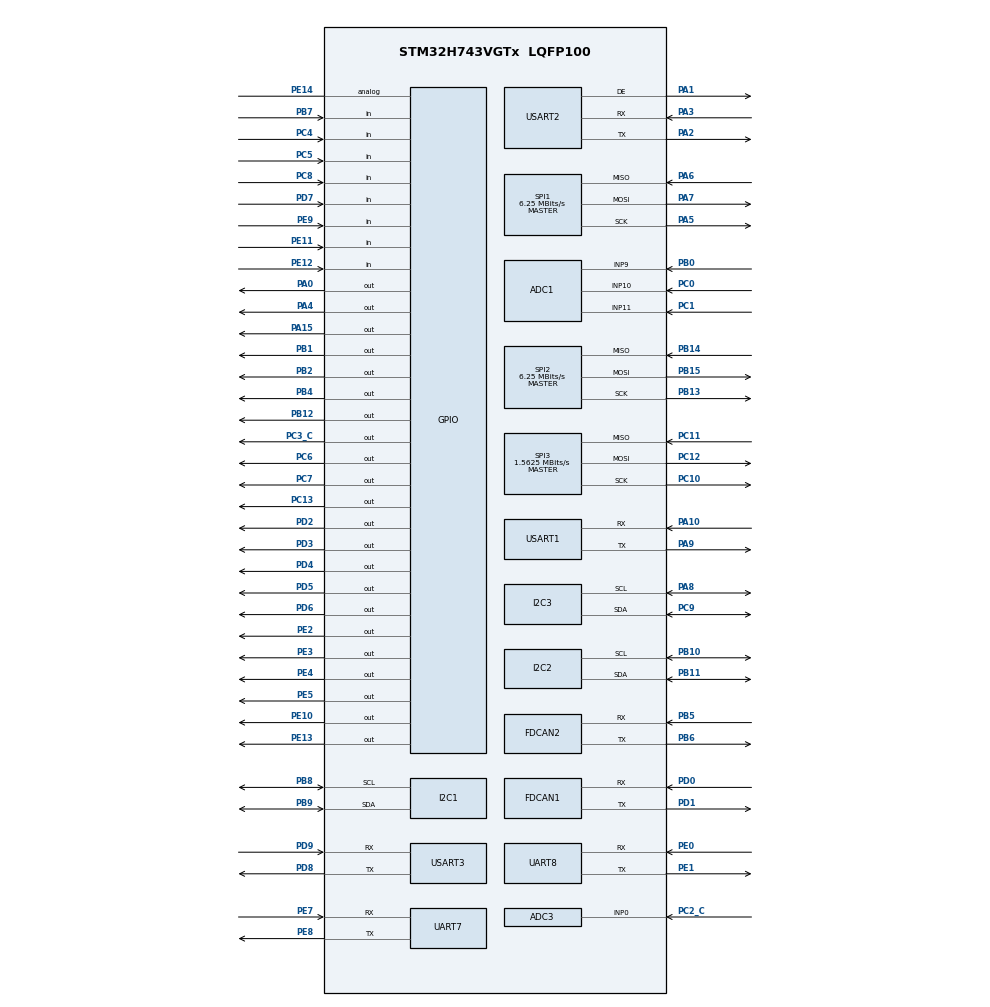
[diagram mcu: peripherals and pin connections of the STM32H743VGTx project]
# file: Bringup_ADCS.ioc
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ADC1.Channel-1\#ChannelRegularConversion=ADC_CHANNEL_9
ADC1.ClockPrescaler=ADC_CLOCK_ASYNC_DIV4
ADC1.NbrOfConversionFlag=1
ADC1.OffsetNumber-1\#ChannelRegularConversion=ADC_OFFSET_NONE
ADC1.OffsetSignedSaturation-1\#ChannelRegularConversion=DISABLE
ADC1.Rank-1\#ChannelRegularConversion=1
ADC1.SamplingTime-1\#ChannelRegularConversion=ADC_SAMPLETIME_810CYCLES_5
ADC1.master=1
ADC3.Channel-1\#ChannelRegularConversion=ADC_CHANNEL_0
ADC3.ClockPrescaler=ADC_CLOCK_ASYNC_DIV4
ADC3.NbrOfConversionFlag=1
ADC3.OffsetNumber-1\#ChannelRegularConversion=ADC_OFFSET_NONE
ADC3.OffsetSignedSaturation-1\#ChannelRegularConversion=DISABLE
ADC3.Rank-1\#ChannelRegularConversion=1
ADC3.SamplingTime-1\#ChannelRegularConversion=ADC_SAMPLETIME_1CYCLE_5
CORTEX_M7.default_mode_Activation=1
FDCAN1.AutoRetransmission=ENABLE
FDCAN1.CalculateBaudRateNominal=500000
FDCAN1.CalculateTimeBitNominal=2000
FDCAN1.CalculateTimeQuantumNominal=100.0
FDCAN1.NominalPrescaler=5
FDCAN1.NominalTimeSeg1=15
FDCAN1.NominalTimeSeg2=4
FDCAN1.RxFifo0ElmtsNbr=8
FDCAN1.StdFiltersNbr=1
FDCAN1.TxFifoQueueElmtsNbr=8
FDCAN2.AutoRetransmission=ENABLE
FDCAN2.CalculateBaudRateNominal=500000
FDCAN2.CalculateTimeBitNominal=2000
FDCAN2.CalculateTimeQuantumNominal=100.0
FDCAN2.MessageRAMOffset=128
FDCAN2.NominalPrescaler=5
FDCAN2.NominalTimeSeg1=15
FDCAN2.NominalTimeSeg2=4
FDCAN2.RxFifo0ElmtsNbr=8
FDCAN2.StdFiltersNbr=1
FDCAN2.TxFifoQueueElmtsNbr=8
FREERTOS.Tasks01=defaultTask,24,128,StartDefaultTask,Default,NULL,Dynamic,NULL,NULL
I2C1.Timing=0x00707CBB
I2C2.Timing=0x00707CBB
I2C3.Timing=0x00707CBB
Mcu.Family=STM32H7
Mcu.Name=STM32H743VGTx
Mcu.Package=LQFP100
NVIC.PriorityGroup=NVIC_PRIORITYGROUP_4
NVIC.TIM6_DAC_IRQn=true\:15\:0\:false\:false\:true\:false\:false\:true\:true
NVIC.TimeBase=TIM6_DAC_IRQn
NVIC.TimeBaseIP=TIM6
PA0.Signal=GPIO_Output
PA1.Mode=Hardware Flow Control (RS485)
PA1.Signal=USART2_DE
PA10.Mode=Asynchronous
PA10.Signal=USART1_RX
PA13\ (JTMS/SWDIO).Mode=Serial_Wire
PA13\ (JTMS/SWDIO).Signal=DEBUG_JTMS-SWDIO
PA14\ (JTCK/SWCLK).Mode=Serial_Wire
PA14\ (JTCK/SWCLK).Signal=DEBUG_JTCK-SWCLK
PA15\ (JTDI).Signal=GPIO_Output
PA2.Mode=Asynchronous
PA2.Signal=USART2_TX
PA3.Mode=Asynchronous
PA3.Signal=USART2_RX
PA4.PinState=GPIO_PIN_SET
PA4.Signal=GPIO_Output
PA5.Mode=Full_Duplex_Master
PA5.Signal=SPI1_SCK
PA6.Mode=Full_Duplex_Master
PA6.Signal=SPI1_MISO
PA7.Mode=Full_Duplex_Master
PA7.Signal=SPI1_MOSI
PA8.Mode=I2C
PA8.Signal=I2C3_SCL
PA9.Mode=Asynchronous
PA9.Signal=USART1_TX
PB0.Signal=ADCx_INP9
PB1.Signal=GPIO_Output
PB10.Mode=I2C
PB10.Signal=I2C2_SCL
PB11.Mode=I2C
PB11.Signal=I2C2_SDA
PB12.PinState=GPIO_PIN_SET
PB12.Signal=GPIO_Output
PB13.Mode=Full_Duplex_Master
PB13.Signal=SPI2_SCK
PB14.Mode=Full_Duplex_Master
PB14.Signal=SPI2_MISO
PB15.Mode=Full_Duplex_Master
PB15.Signal=SPI2_MOSI
PB2.Signal=GPIO_Output
PB4\ (NJTRST).Signal=GPIO_Output
PB5.Mode=FDCAN_Activate
PB5.Signal=FDCAN2_RX
PB6.Mode=FDCAN_Activate
PB6.Signal=FDCAN2_TX
PB7.Signal=GPIO_Input
PB8.Mode=I2C
PB8.Signal=I2C1_SCL
PB9.Mode=I2C
PB9.Signal=I2C1_SDA
PC0.Signal=ADCx_INP10
PC1.Signal=ADCx_INP11
PC10.Mode=Full_Duplex_Master
PC10.Signal=SPI3_SCK
PC11.Mode=Full_Duplex_Master
PC11.Signal=SPI3_MISO
PC12.Mode=Full_Duplex_Master
PC12.Signal=SPI3_MOSI
PC13.Signal=GPIO_Output
PC14-OSC32_IN\ (OSC32_IN).Mode=LSE-External-Oscillator
PC14-OSC32_IN\ (OSC32_IN).Signal=RCC_OSC32_IN
PC15-OSC32_OUT\ (OSC32_OUT).Mode=LSE-External-Oscillator
PC15-OSC32_OUT\ (OSC32_OUT).Signal=RCC_OSC32_OUT
PC2_C.Mode=IN0-Single-Ended
PC2_C.Signal=ADC3_INP0
PC3_C.PinState=GPIO_PIN_SET
PC3_C.Signal=GPIO_Output
PC4.Signal=GPIO_Input
PC5.Signal=GPIO_Input
PC6.Signal=GPIO_Output
PC7.Signal=GPIO_Output
PC8.Signal=GPIO_Input
PC9.Mode=I2C
PC9.Signal=I2C3_SDA
PD0.Mode=FDCAN_Activate
PD0.Signal=FDCAN1_RX
PD1.Mode=FDCAN_Activate
PD1.Signal=FDCAN1_TX
PD2.Signal=GPIO_Output
PD3.Signal=GPIO_Output
PD4.Signal=GPIO_Output
PD5.Signal=GPIO_Output
PD6.PinState=GPIO_PIN_SET
PD6.Signal=GPIO_Output
PD7.Signal=GPIO_Input
PD8.Mode=Asynchronous
PD8.Signal=USART3_TX
PD9.Mode=Asynchronous
PD9.Signal=USART3_RX
PE0.Mode=Asynchronous
PE0.Signal=UART8_RX
PE1.Mode=Asynchronous
PE1.Signal=UART8_TX
PE10.Signal=GPIO_Output
PE11.Signal=GPIO_Input
PE12.Signal=GPIO_Input
PE13.Signal=GPIO_Output
PE14.Signal=GPIO_Analog
PE2.Signal=GPIO_Output
PE3.Signal=GPIO_Output
PE4.Signal=GPIO_Output
PE5.Signal=GPIO_Output
PE7.Mode=Asynchronous
PE7.Signal=UART7_RX
PE8.Mode=Asynchronous
PE8.Signal=UART7_TX
PE9.Signal=GPIO_Input
PH0-OSC_IN\ (PH0).Mode=HSE-External-Oscillator
PH0-OSC_IN\ (PH0).Signal=RCC_OSC_IN
PH1-OSC_OUT\ (PH1).Mode=HSE-External-Oscillator
PH1-OSC_OUT\ (PH1).Signal=RCC_OSC_OUT
ProjectManager.HeapSize=0x200
ProjectManager.StackSize=0x400
ProjectManager.TargetToolchain=CMake
RCC.ADCFreq_Value=75000000
RCC.APB1Freq_Value=32000000
RCC.APB2Freq_Value=32000000
RCC.APB3Freq_Value=64000000
RCC.APB4Freq_Value=64000000
RCC.CKPERSourceSelection=RCC_CLKPSOURCE_HSE
RCC.CortexFreq_Value=64000000
RCC.D2PPRE1=RCC_APB1_DIV2
RCC.D2PPRE2=RCC_APB2_DIV2
RCC.DIVM1=2
RCC.DIVM2=2
RCC.DIVN1=12
RCC.DIVN2=12
RCC.DIVQ1=3
RCC.HCLKFreq_Value=64000000
RCC.PLL2FRACN=0
RCC.PLLFRACN=0
RCC.PLLSourceVirtual=RCC_PLLSOURCE_HSE
RCC.SYSCLKFreq_VALUE=64000000
RCC.USBFreq_Value=50000000
SH.ADCx_INP10.0=ADC1_INP10,IN10-Single-Ended
SH.ADCx_INP11.0=ADC1_INP11,IN11-Single-Ended
SH.ADCx_INP9.0=ADC1_INP9,IN9-Single-Ended
SPI1.BaudRatePrescaler=SPI_BAUDRATEPRESCALER_8
SPI1.CalculateBaudRate=6.25 MBits/s
SPI1.DataSize=SPI_DATASIZE_8BIT
SPI1.Direction=SPI_DIRECTION_2LINES
SPI1.Mode=SPI_MODE_MASTER
SPI1.VirtualType=VM_MASTER
SPI2.BaudRatePrescaler=SPI_BAUDRATEPRESCALER_8
SPI2.CalculateBaudRate=6.25 MBits/s
SPI2.DataSize=SPI_DATASIZE_8BIT
SPI2.Direction=SPI_DIRECTION_2LINES
SPI2.Mode=SPI_MODE_MASTER
SPI2.VirtualType=VM_MASTER
SPI3.BaudRatePrescaler=SPI_BAUDRATEPRESCALER_32
SPI3.CLKPhase=SPI_PHASE_2EDGE
SPI3.CalculateBaudRate=1.5625 MBits/s
SPI3.DataSize=SPI_DATASIZE_16BIT
SPI3.Direction=SPI_DIRECTION_2LINES
SPI3.Mode=SPI_MODE_MASTER
SPI3.VirtualType=VM_MASTER
USART1.VirtualMode-Asynchronous=VM_ASYNC
USART2.VirtualMode-Asynchronous=VM_ASYNC
USART2.VirtualMode-Hardware\ Flow\ Control\ (RS485)=VM_ASYNC
USART3.VirtualMode-Asynchronous=VM_ASYNC
VP_FREERTOS_VS_CMSIS_V2.Mode=CMSIS_V2
VP_MEMORYMAP_VS_MEMORYMAP.Mode=CurAppReg
VP_SYS_VS_tim6.Mode=TIM6
board=custom

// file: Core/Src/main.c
/* USER CODE BEGIN Header */
/**
  ******************************************************************************
  * @file           : main.c
  * @brief          : Main program body
  ******************************************************************************
  * @attention
  *
  * Copyright (c) 2026 STMicroelectronics.
  * All rights reserved.
  *
  * This software is licensed under terms that can be found in the LICENSE file
  * in the root directory of this software component.
  * If no LICENSE file comes with this software, it is provided AS-IS.
  *
  ******************************************************************************
  */
/* USER CODE END Header */
#include "main.h"
#include "cmsis_os.h"

/* USER CODE BEGIN Includes */
#include "app_tasks.h"
/* USER CODE END Includes */

ADC_HandleTypeDef hadc1;
ADC_HandleTypeDef hadc3;

FDCAN_HandleTypeDef hfdcan1;
FDCAN_HandleTypeDef hfdcan2;

I2C_HandleTypeDef hi2c1;
I2C_HandleTypeDef hi2c2;
I2C_HandleTypeDef hi2c3;

SPI_HandleTypeDef hspi1;
SPI_HandleTypeDef hspi2;
SPI_HandleTypeDef hspi3;

UART_HandleTypeDef huart7;
UART_HandleTypeDef huart8;
UART_HandleTypeDef huart1;
UART_HandleTypeDef huart2;
UART_HandleTypeDef huart3;

/* Definitions for defaultTask */
osThreadId_t defaultTaskHandle;
const osThreadAttr_t defaultTask_attributes = {
  .name = "defaultTask",
  .stack_size = 128 * 4,
  .priority = (osPriority_t) osPriorityNormal,
};

void SystemClock_Config(void);
void PeriphCommonClock_Config(void);
static void MPU_Config(void);
static void MX_GPIO_Init(void);
static void MX_ADC1_Init(void);
static void MX_ADC3_Init(void);
static void MX_FDCAN1_Init(void);
static void MX_FDCAN2_Init(void);
static void MX_I2C1_Init(void);
static void MX_I2C2_Init(void);
static void MX_I2C3_Init(void);
static void MX_SPI1_Init(void);
static void MX_SPI2_Init(void);
static void MX_SPI3_Init(void);
static void MX_UART7_Init(void);
static void MX_UART8_Init(void);
static void MX_USART1_UART_Init(void);
static void MX_USART2_UART_Init(void);
static void MX_USART3_UART_Init(void);
void StartDefaultTask(void *argument);

int main(void)
{

  /* MPU Configuration--------------------------------------------------------*/
  MPU_Config();

  /* MCU Configuration--------------------------------------------------------*/

  /* Reset of all peripherals, Initializes the Flash interface and the Systick. */
  HAL_Init();

  /* Configure the system clock */
  SystemClock_Config();

  /* Configure the peripherals common clocks */
  PeriphCommonClock_Config();

  /* Initialize all configured peripherals */
  MX_GPIO_Init();
  MX_ADC1_Init();
  MX_ADC3_Init();
  MX_FDCAN1_Init();
  MX_FDCAN2_Init();
  MX_I2C1_Init();
  MX_I2C2_Init();
  MX_I2C3_Init();
  MX_SPI1_Init();
  MX_SPI2_Init();
  MX_SPI3_Init();
  MX_UART7_Init();
  MX_UART8_Init();
  MX_USART1_UART_Init();
  MX_USART2_UART_Init();
  MX_USART3_UART_Init();

  /* Init scheduler */
  osKernelInitialize();

  /* Create the thread(s) */
  /* creation of defaultTask */
  defaultTaskHandle = osThreadNew(StartDefaultTask, NULL, &defaultTask_attributes);

  /* USER CODE BEGIN RTOS_THREADS */
  app_tasks_init();
  /* USER CODE END RTOS_THREADS */

  /* Start scheduler */
  osKernelStart();

  /* We should never get here as control is now taken by the scheduler */

  /* Infinite loop */
  while (1)
  {

  }
}

void SystemClock_Config(void)
{
  RCC_OscInitTypeDef RCC_OscInitStruct = {0};
  RCC_ClkInitTypeDef RCC_ClkInitStruct = {0};

  /** Supply configuration update enable
  */
  HAL_PWREx_ConfigSupply(PWR_LDO_SUPPLY);

  /** Configure the main internal regulator output voltage
  */
  __HAL_PWR_VOLTAGESCALING_CONFIG(PWR_REGULATOR_VOLTAGE_SCALE3);

  while(!__HAL_PWR_GET_FLAG(PWR_FLAG_VOSRDY)) {}

  /** Initializes the RCC Oscillators according to the specified parameters
  * in the RCC_OscInitTypeDef structure.
  */
  RCC_OscInitStruct.OscillatorType = RCC_OSCILLATORTYPE_HSI|RCC_OSCILLATORTYPE_HSE;
  RCC_OscInitStruct.HSEState = RCC_HSE_ON;
  RCC_OscInitStruct.HSIState = RCC_HSI_DIV1;
  RCC_OscInitStruct.HSICalibrationValue = RCC_HSICALIBRATION_DEFAULT;
  RCC_OscInitStruct.PLL.PLLState = RCC_PLL_ON;
  RCC_OscInitStruct.PLL.PLLSource = RCC_PLLSOURCE_HSE;
  RCC_OscInitStruct.PLL.PLLM = 2;
  RCC_OscInitStruct.PLL.PLLN = 12;
  RCC_OscInitStruct.PLL.PLLP = 2;
  RCC_OscInitStruct.PLL.PLLQ = 3;
  RCC_OscInitStruct.PLL.PLLR = 2;
  RCC_OscInitStruct.PLL.PLLRGE = RCC_PLL1VCIRANGE_3;
  RCC_OscInitStruct.PLL.PLLVCOSEL = RCC_PLL1VCOMEDIUM;
  RCC_OscInitStruct.PLL.PLLFRACN = 0;
  if (HAL_RCC_OscConfig(&RCC_OscInitStruct) != HAL_OK)
  {
    Error_Handler();
  }

  /** Initializes the CPU, AHB and APB buses clocks
  */
  RCC_ClkInitStruct.ClockType = RCC_CLOCKTYPE_HCLK|RCC_CLOCKTYPE_SYSCLK
                              |RCC_CLOCKTYPE_PCLK1|RCC_CLOCKTYPE_PCLK2
                              |RCC_CLOCKTYPE_D3PCLK1|RCC_CLOCKTYPE_D1PCLK1;
  RCC_ClkInitStruct.SYSCLKSource = RCC_SYSCLKSOURCE_HSI;
  RCC_ClkInitStruct.SYSCLKDivider = RCC_SYSCLK_DIV1;
  RCC_ClkInitStruct.AHBCLKDivider = RCC_HCLK_DIV1;
  RCC_ClkInitStruct.APB3CLKDivider = RCC_APB3_DIV1;
  RCC_ClkInitStruct.APB1CLKDivider = RCC_APB1_DIV2;
  RCC_ClkInitStruct.APB2CLKDivider = RCC_APB2_DIV2;
  RCC_ClkInitStruct.APB4CLKDivider = RCC_APB4_DIV1;

  if (HAL_RCC_ClockConfig(&RCC_ClkInitStruct, FLASH_LATENCY_1) != HAL_OK)
  {
    Error_Handler();
  }
}

void PeriphCommonClock_Config(void)
{
  RCC_PeriphCLKInitTypeDef PeriphClkInitStruct = {0};

  /** Initializes the peripherals clock
  */
  PeriphClkInitStruct.PeriphClockSelection = RCC_PERIPHCLK_ADC;
  PeriphClkInitStruct.PLL2.PLL2M = 2;
  PeriphClkInitStruct.PLL2.PLL2N = 12;
  PeriphClkInitStruct.PLL2.PLL2P = 2;
  PeriphClkInitStruct.PLL2.PLL2Q = 2;
  PeriphClkInitStruct.PLL2.PLL2R = 2;
  PeriphClkInitStruct.PLL2.PLL2RGE = RCC_PLL2VCIRANGE_3;
  PeriphClkInitStruct.PLL2.PLL2VCOSEL = RCC_PLL2VCOMEDIUM;
  PeriphClkInitStruct.PLL2.PLL2FRACN = 0;
  PeriphClkInitStruct.AdcClockSelection = RCC_ADCCLKSOURCE_PLL2;
  if (HAL_RCCEx_PeriphCLKConfig(&PeriphClkInitStruct) != HAL_OK)
  {
    Error_Handler();
  }
}

static void MX_ADC1_Init(void)
{

  ADC_MultiModeTypeDef multimode = {0};
  ADC_ChannelConfTypeDef sConfig = {0};

  /** Common config
  */
  hadc1.Instance = ADC1;
  hadc1.Init.ClockPrescaler = ADC_CLOCK_ASYNC_DIV4;
  hadc1.Init.Resolution = ADC_RESOLUTION_16B;
  hadc1.Init.ScanConvMode = ADC_SCAN_DISABLE;
  hadc1.Init.EOCSelection = ADC_EOC_SINGLE_CONV;
  hadc1.Init.LowPowerAutoWait = DISABLE;
  hadc1.Init.ContinuousConvMode = DISABLE;
  hadc1.Init.NbrOfConversion = 1;
  hadc1.Init.DiscontinuousConvMode = DISABLE;
  hadc1.Init.ExternalTrigConv = ADC_SOFTWARE_START;
  hadc1.Init.ExternalTrigConvEdge = ADC_EXTERNALTRIGCONVEDGE_NONE;
  hadc1.Init.ConversionDataManagement = ADC_CONVERSIONDATA_DR;
  hadc1.Init.Overrun = ADC_OVR_DATA_PRESERVED;
  hadc1.Init.LeftBitShift = ADC_LEFTBITSHIFT_NONE;
  hadc1.Init.OversamplingMode = DISABLE;
  hadc1.Init.Oversampling.Ratio = 1;
  if (HAL_ADC_Init(&hadc1) != HAL_OK)
  {
    Error_Handler();
  }

  /** Configure the ADC multi-mode
  */
  multimode.Mode = ADC_MODE_INDEPENDENT;
  if (HAL_ADCEx_MultiModeConfigChannel(&hadc1, &multimode) != HAL_OK)
  {
    Error_Handler();
  }

  /** Configure Regular Channel
  */
  sConfig.Channel = ADC_CHANNEL_9;
  sConfig.Rank = ADC_REGULAR_RANK_1;
  sConfig.SamplingTime = ADC_SAMPLETIME_810CYCLES_5;
  sConfig.SingleDiff = ADC_SINGLE_ENDED;
  sConfig.OffsetNumber = ADC_OFFSET_NONE;
  sConfig.Offset = 0;
  sConfig.OffsetSignedSaturation = DISABLE;
  if (HAL_ADC_ConfigChannel(&hadc1, &sConfig) != HAL_OK)
  {
    Error_Handler();
  }

}

static void MX_ADC3_Init(void)
{

  ADC_ChannelConfTypeDef sConfig = {0};

  /** Common config
  */
  hadc3.Instance = ADC3;
  hadc3.Init.ClockPrescaler = ADC_CLOCK_ASYNC_DIV4;
  hadc3.Init.Resolution = ADC_RESOLUTION_16B;
  hadc3.Init.ScanConvMode = ADC_SCAN_DISABLE;
  hadc3.Init.EOCSelection = ADC_EOC_SINGLE_CONV;
  hadc3.Init.LowPowerAutoWait = DISABLE;
  hadc3.Init.ContinuousConvMode = DISABLE;
  hadc3.Init.NbrOfConversion = 1;
  hadc3.Init.DiscontinuousConvMode = DISABLE;
  hadc3.Init.ExternalTrigConv = ADC_SOFTWARE_START;
  hadc3.Init.ExternalTrigConvEdge = ADC_EXTERNALTRIGCONVEDGE_NONE;
  hadc3.Init.ConversionDataManagement = ADC_CONVERSIONDATA_DR;
  hadc3.Init.Overrun = ADC_OVR_DATA_PRESERVED;
  hadc3.Init.LeftBitShift = ADC_LEFTBITSHIFT_NONE;
  hadc3.Init.OversamplingMode = DISABLE;
  hadc3.Init.Oversampling.Ratio = 1;
  if (HAL_ADC_Init(&hadc3) != HAL_OK)
  {
    Error_Handler();
  }

  /** Configure Regular Channel
  */
  sConfig.Channel = ADC_CHANNEL_0;
  sConfig.Rank = ADC_REGULAR_RANK_1;
  sConfig.SamplingTime = ADC_SAMPLETIME_1CYCLE_5;
  sConfig.SingleDiff = ADC_SINGLE_ENDED;
  sConfig.OffsetNumber = ADC_OFFSET_NONE;
  sConfig.Offset = 0;
  sConfig.OffsetSignedSaturation = DISABLE;
  if (HAL_ADC_ConfigChannel(&hadc3, &sConfig) != HAL_OK)
  {
    Error_Handler();
  }

}

static void MX_FDCAN1_Init(void)
{

  hfdcan1.Instance = FDCAN1;
  hfdcan1.Init.FrameFormat = FDCAN_FRAME_CLASSIC;
  hfdcan1.Init.Mode = FDCAN_MODE_NORMAL;
  hfdcan1.Init.AutoRetransmission = ENABLE;
  hfdcan1.Init.TransmitPause = DISABLE;
  hfdcan1.Init.ProtocolException = DISABLE;
  hfdcan1.Init.NominalPrescaler = 5;
  hfdcan1.Init.NominalSyncJumpWidth = 1;
  hfdcan1.Init.NominalTimeSeg1 = 15;
  hfdcan1.Init.NominalTimeSeg2 = 4;
  hfdcan1.Init.DataPrescaler = 1;
  hfdcan1.Init.DataSyncJumpWidth = 1;
  hfdcan1.Init.DataTimeSeg1 = 1;
  hfdcan1.Init.DataTimeSeg2 = 1;
  hfdcan1.Init.MessageRAMOffset = 0;
  hfdcan1.Init.StdFiltersNbr = 1;
  hfdcan1.Init.ExtFiltersNbr = 0;
  hfdcan1.Init.RxFifo0ElmtsNbr = 8;
  hfdcan1.Init.RxFifo0ElmtSize = FDCAN_DATA_BYTES_8;
  hfdcan1.Init.RxFifo1ElmtsNbr = 0;
  hfdcan1.Init.RxFifo1ElmtSize = FDCAN_DATA_BYTES_8;
  hfdcan1.Init.RxBuffersNbr = 0;
  hfdcan1.Init.RxBufferSize = FDCAN_DATA_BYTES_8;
  hfdcan1.Init.TxEventsNbr = 0;
  hfdcan1.Init.TxBuffersNbr = 0;
  hfdcan1.Init.TxFifoQueueElmtsNbr = 8;
  hfdcan1.Init.TxFifoQueueMode = FDCAN_TX_FIFO_OPERATION;
  hfdcan1.Init.TxElmtSize = FDCAN_DATA_BYTES_8;
  if (HAL_FDCAN_Init(&hfdcan1) != HAL_OK)
  {
    Error_Handler();
  }

}

static void MX_FDCAN2_Init(void)
{

  hfdcan2.Instance = FDCAN2;
  hfdcan2.Init.FrameFormat = FDCAN_FRAME_CLASSIC;
  hfdcan2.Init.Mode = FDCAN_MODE_NORMAL;
  hfdcan2.Init.AutoRetransmission = ENABLE;
  hfdcan2.Init.TransmitPause = DISABLE;
  hfdcan2.Init.ProtocolException = DISABLE;
  hfdcan2.Init.NominalPrescaler = 5;
  hfdcan2.Init.NominalSyncJumpWidth = 1;
  hfdcan2.Init.NominalTimeSeg1 = 15;
  hfdcan2.Init.NominalTimeSeg2 = 4;
  hfdcan2.Init.DataPrescaler = 1;
  hfdcan2.Init.DataSyncJumpWidth = 1;
  hfdcan2.Init.DataTimeSeg1 = 1;
  hfdcan2.Init.DataTimeSeg2 = 1;
  hfdcan2.Init.MessageRAMOffset = 128;
  hfdcan2.Init.StdFiltersNbr = 1;
  hfdcan2.Init.ExtFiltersNbr = 0;
  hfdcan2.Init.RxFifo0ElmtsNbr = 8;
  hfdcan2.Init.RxFifo0ElmtSize = FDCAN_DATA_BYTES_8;
  hfdcan2.Init.RxFifo1ElmtsNbr = 0;
  hfdcan2.Init.RxFifo1ElmtSize = FDCAN_DATA_BYTES_8;
  hfdcan2.Init.RxBuffersNbr = 0;
  hfdcan2.Init.RxBufferSize = FDCAN_DATA_BYTES_8;
  hfdcan2.Init.TxEventsNbr = 0;
  hfdcan2.Init.TxBuffersNbr = 0;
  hfdcan2.Init.TxFifoQueueElmtsNbr = 8;
  hfdcan2.Init.TxFifoQueueMode = FDCAN_TX_FIFO_OPERATION;
  hfdcan2.Init.TxElmtSize = FDCAN_DATA_BYTES_8;
  if (HAL_FDCAN_Init(&hfdcan2) != HAL_OK)
  {
    Error_Handler();
  }

}

static void MX_I2C1_Init(void)
{

  hi2c1.Instance = I2C1;
  hi2c1.Init.Timing = 0x00707CBB;
  hi2c1.Init.OwnAddress1 = 0;
  hi2c1.Init.AddressingMode = I2C_ADDRESSINGMODE_7BIT;
  hi2c1.Init.DualAddressMode = I2C_DUALADDRESS_DISABLE;
  hi2c1.Init.OwnAddress2 = 0;
  hi2c1.Init.OwnAddress2Masks = I2C_OA2_NOMASK;
  hi2c1.Init.GeneralCallMode = I2C_GENERALCALL_DISABLE;
  hi2c1.Init.NoStretchMode = I2C_NOSTRETCH_DISABLE;
  if (HAL_I2C_Init(&hi2c1) != HAL_OK)
  {
    Error_Handler();
  }

  /** Configure Analogue filter
  */
  if (HAL_I2CEx_ConfigAnalogFilter(&hi2c1, I2C_ANALOGFILTER_ENABLE) != HAL_OK)
  {
    Error_Handler();
  }

  /** Configure Digital filter
  */
  if (HAL_I2CEx_ConfigDigitalFilter(&hi2c1, 0) != HAL_OK)
  {
    Error_Handler();
  }

}

static void MX_I2C2_Init(void)
{

  hi2c2.Instance = I2C2;
  hi2c2.Init.Timing = 0x00707CBB;
  hi2c2.Init.OwnAddress1 = 0;
  hi2c2.Init.AddressingMode = I2C_ADDRESSINGMODE_7BIT;
  hi2c2.Init.DualAddressMode = I2C_DUALADDRESS_DISABLE;
  hi2c2.Init.OwnAddress2 = 0;
  hi2c2.Init.OwnAddress2Masks = I2C_OA2_NOMASK;
  hi2c2.Init.GeneralCallMode = I2C_GENERALCALL_DISABLE;
  hi2c2.Init.NoStretchMode = I2C_NOSTRETCH_DISABLE;
  if (HAL_I2C_Init(&hi2c2) != HAL_OK)
  {
    Error_Handler();
  }

  /** Configure Analogue filter
  */
  if (HAL_I2CEx_ConfigAnalogFilter(&hi2c2, I2C_ANALOGFILTER_ENABLE) != HAL_OK)
  {
    Error_Handler();
  }

  /** Configure Digital filter
  */
  if (HAL_I2CEx_ConfigDigitalFilter(&hi2c2, 0) != HAL_OK)
  {
    Error_Handler();
  }

}

static void MX_I2C3_Init(void)
{

  hi2c3.Instance = I2C3;
  hi2c3.Init.Timing = 0x00707CBB;
  hi2c3.Init.OwnAddress1 = 0;
  hi2c3.Init.AddressingMode = I2C_ADDRESSINGMODE_7BIT;
  hi2c3.Init.DualAddressMode = I2C_DUALADDRESS_DISABLE;
  hi2c3.Init.OwnAddress2 = 0;
  hi2c3.Init.OwnAddress2Masks = I2C_OA2_NOMASK;
  hi2c3.Init.GeneralCallMode = I2C_GENERALCALL_DISABLE;
  hi2c3.Init.NoStretchMode = I2C_NOSTRETCH_DISABLE;
  if (HAL_I2C_Init(&hi2c3) != HAL_OK)
  {
    Error_Handler();
  }

  /** Configure Analogue filter
  */
  if (HAL_I2CEx_ConfigAnalogFilter(&hi2c3, I2C_ANALOGFILTER_ENABLE) != HAL_OK)
  {
    Error_Handler();
  }

  /** Configure Digital filter
  */
  if (HAL_I2CEx_ConfigDigitalFilter(&hi2c3, 0) != HAL_OK)
  {
    Error_Handler();
  }

}

static void MX_SPI1_Init(void)
{

  /* SPI1 parameter configuration*/
  hspi1.Instance = SPI1;
  hspi1.Init.Mode = SPI_MODE_MASTER;
  hspi1.Init.Direction = SPI_DIRECTION_2LINES;
  hspi1.Init.DataSize = SPI_DATASIZE_8BIT;
  hspi1.Init.CLKPolarity = SPI_POLARITY_LOW;
  hspi1.Init.CLKPhase = SPI_PHASE_1EDGE;
  hspi1.Init.NSS = SPI_NSS_SOFT;
  hspi1.Init.BaudRatePrescaler = SPI_BAUDRATEPRESCALER_8;
  hspi1.Init.FirstBit = SPI_FIRSTBIT_MSB;
  hspi1.Init.TIMode = SPI_TIMODE_DISABLE;
  hspi1.Init.CRCCalculation = SPI_CRCCALCULATION_DISABLE;
  hspi1.Init.CRCPolynomial = 0x0;
  hspi1.Init.NSSPMode = SPI_NSS_PULSE_ENABLE;
  hspi1.Init.NSSPolarity = SPI_NSS_POLARITY_LOW;
  hspi1.Init.FifoThreshold = SPI_FIFO_THRESHOLD_01DATA;
  hspi1.Init.TxCRCInitializationPattern = SPI_CRC_INITIALIZATION_ALL_ZERO_PATTERN;
  hspi1.Init.RxCRCInitializationPattern = SPI_CRC_INITIALIZATION_ALL_ZERO_PATTERN;
  hspi1.Init.MasterSSIdleness = SPI_MASTER_SS_IDLENESS_00CYCLE;
  hspi1.Init.MasterInterDataIdleness = SPI_MASTER_INTERDATA_IDLENESS_00CYCLE;
  hspi1.Init.MasterReceiverAutoSusp = SPI_MASTER_RX_AUTOSUSP_DISABLE;
  hspi1.Init.MasterKeepIOState = SPI_MASTER_KEEP_IO_STATE_DISABLE;
  hspi1.Init.IOSwap = SPI_IO_SWAP_DISABLE;
  if (HAL_SPI_Init(&hspi1) != HAL_OK)
  {
    Error_Handler();
  }

}

static void MX_SPI2_Init(void)
{

  /* SPI2 parameter configuration*/
  hspi2.Instance = SPI2;
  hspi2.Init.Mode = SPI_MODE_MASTER;
  hspi2.Init.Direction = SPI_DIRECTION_2LINES;
  hspi2.Init.DataSize = SPI_DATASIZE_8BIT;
  hspi2.Init.CLKPolarity = SPI_POLARITY_LOW;
  hspi2.Init.CLKPhase = SPI_PHASE_1EDGE;
  hspi2.Init.NSS = SPI_NSS_SOFT;
  hspi2.Init.BaudRatePrescaler = SPI_BAUDRATEPRESCALER_8;
  hspi2.Init.FirstBit = SPI_FIRSTBIT_MSB;
  hspi2.Init.TIMode = SPI_TIMODE_DISABLE;
  hspi2.Init.CRCCalculation = SPI_CRCCALCULATION_DISABLE;
  hspi2.Init.CRCPolynomial = 0x0;
  hspi2.Init.NSSPMode = SPI_NSS_PULSE_ENABLE;
  hspi2.Init.NSSPolarity = SPI_NSS_POLARITY_LOW;
  hspi2.Init.FifoThreshold = SPI_FIFO_THRESHOLD_01DATA;
  hspi2.Init.TxCRCInitializationPattern = SPI_CRC_INITIALIZATION_ALL_ZERO_PATTERN;
  hspi2.Init.RxCRCInitializationPattern = SPI_CRC_INITIALIZATION_ALL_ZERO_PATTERN;
  hspi2.Init.MasterSSIdleness = SPI_MASTER_SS_IDLENESS_00CYCLE;
  hspi2.Init.MasterInterDataIdleness = SPI_MASTER_INTERDATA_IDLENESS_00CYCLE;
  hspi2.Init.MasterReceiverAutoSusp = SPI_MASTER_RX_AUTOSUSP_DISABLE;
  hspi2.Init.MasterKeepIOState = SPI_MASTER_KEEP_IO_STATE_DISABLE;
  hspi2.Init.IOSwap = SPI_IO_SWAP_DISABLE;
  if (HAL_SPI_Init(&hspi2) != HAL_OK)
  {
    Error_Handler();
  }

}

static void MX_SPI3_Init(void)
{

  /* SPI3 parameter configuration*/
  hspi3.Instance = SPI3;
  hspi3.Init.Mode = SPI_MODE_MASTER;
  hspi3.Init.Direction = SPI_DIRECTION_2LINES;
  hspi3.Init.DataSize = SPI_DATASIZE_16BIT;
  hspi3.Init.CLKPolarity = SPI_POLARITY_LOW;
  hspi3.Init.CLKPhase = SPI_PHASE_2EDGE;
  hspi3.Init.NSS = SPI_NSS_SOFT;
  hspi3.Init.BaudRatePrescaler = SPI_BAUDRATEPRESCALER_32;
  hspi3.Init.FirstBit = SPI_FIRSTBIT_MSB;
  hspi3.Init.TIMode = SPI_TIMODE_DISABLE;
  hspi3.Init.CRCCalculation = SPI_CRCCALCULATION_DISABLE;
  hspi3.Init.CRCPolynomial = 0x0;
  hspi3.Init.NSSPMode = SPI_NSS_PULSE_ENABLE;
  hspi3.Init.NSSPolarity = SPI_NSS_POLARITY_LOW;
  hspi3.Init.FifoThreshold = SPI_FIFO_THRESHOLD_01DATA;
  hspi3.Init.TxCRCInitializationPattern = SPI_CRC_INITIALIZATION_ALL_ZERO_PATTERN;
  hspi3.Init.RxCRCInitializationPattern = SPI_CRC_INITIALIZATION_ALL_ZERO_PATTERN;
  hspi3.Init.MasterSSIdleness = SPI_MASTER_SS_IDLENESS_00CYCLE;
  hspi3.Init.MasterInterDataIdleness = SPI_MASTER_INTERDATA_IDLENESS_00CYCLE;
  hspi3.Init.MasterReceiverAutoSusp = SPI_MASTER_RX_AUTOSUSP_DISABLE;
  hspi3.Init.MasterKeepIOState = SPI_MASTER_KEEP_IO_STATE_DISABLE;
  hspi3.Init.IOSwap = SPI_IO_SWAP_DISABLE;
  if (HAL_SPI_Init(&hspi3) != HAL_OK)
  {
    Error_Handler();
  }

}

static void MX_UART7_Init(void)
{

  huart7.Instance = UART7;
  huart7.Init.BaudRate = 115200;
  huart7.Init.WordLength = UART_WORDLENGTH_8B;
  huart7.Init.StopBits = UART_STOPBITS_1;
  huart7.Init.Parity = UART_PARITY_NONE;
  huart7.Init.Mode = UART_MODE_TX_RX;
  huart7.Init.HwFlowCtl = UART_HWCONTROL_NONE;
  huart7.Init.OverSampling = UART_OVERSAMPLING_16;
  huart7.Init.OneBitSampling = UART_ONE_BIT_SAMPLE_DISABLE;
  huart7.Init.ClockPrescaler = UART_PRESCALER_DIV1;
  huart7.AdvancedInit.AdvFeatureInit = UART_ADVFEATURE_NO_INIT;
  if (HAL_UART_Init(&huart7) != HAL_OK)
  {
    Error_Handler();
  }
  if (HAL_UARTEx_SetTxFifoThreshold(&huart7, UART_TXFIFO_THRESHOLD_1_8) != HAL_OK)
  {
    Error_Handler();
  }
  if (HAL_UARTEx_SetRxFifoThreshold(&huart7, UART_RXFIFO_THRESHOLD_1_8) != HAL_OK)
  {
    Error_Handler();
  }
  if (HAL_UARTEx_DisableFifoMode(&huart7) != HAL_OK)
  {
    Error_Handler();
  }

}

static void MX_UART8_Init(void)
{

  huart8.Instance = UART8;
  huart8.Init.BaudRate = 115200;
  huart8.Init.WordLength = UART_WORDLENGTH_8B;
  huart8.Init.StopBits = UART_STOPBITS_1;
  huart8.Init.Parity = UART_PARITY_NONE;
  huart8.Init.Mode = UART_MODE_TX_RX;
  huart8.Init.HwFlowCtl = UART_HWCONTROL_NONE;
  huart8.Init.OverSampling = UART_OVERSAMPLING_16;
  huart8.Init.OneBitSampling = UART_ONE_BIT_SAMPLE_DISABLE;
  huart8.Init.ClockPrescaler = UART_PRESCALER_DIV1;
  huart8.AdvancedInit.AdvFeatureInit = UART_ADVFEATURE_NO_INIT;
  if (HAL_UART_Init(&huart8) != HAL_OK)
  {
    Error_Handler();
  }
  if (HAL_UARTEx_SetTxFifoThreshold(&huart8, UART_TXFIFO_THRESHOLD_1_8) != HAL_OK)
  {
    Error_Handler();
  }
  if (HAL_UARTEx_SetRxFifoThreshold(&huart8, UART_RXFIFO_THRESHOLD_1_8) != HAL_OK)
  {
    Error_Handler();
  }
  if (HAL_UARTEx_DisableFifoMode(&huart8) != HAL_OK)
  {
    Error_Handler();
  }

}

static void MX_USART1_UART_Init(void)
{

  huart1.Instance = USART1;
  huart1.Init.BaudRate = 115200;
  huart1.Init.WordLength = UART_WORDLENGTH_8B;
  huart1.Init.StopBits = UART_STOPBITS_1;
  huart1.Init.Parity = UART_PARITY_NONE;
  huart1.Init.Mode = UART_MODE_TX_RX;
  huart1.Init.HwFlowCtl = UART_HWCONTROL_NONE;
  huart1.Init.OverSampling = UART_OVERSAMPLING_16;
  huart1.Init.OneBitSampling = UART_ONE_BIT_SAMPLE_DISABLE;
  huart1.Init.ClockPrescaler = UART_PRESCALER_DIV1;
  huart1.AdvancedInit.AdvFeatureInit = UART_ADVFEATURE_NO_INIT;
  if (HAL_UART_Init(&huart1) != HAL_OK)
  {
    Error_Handler();
  }
  if (HAL_UARTEx_SetTxFifoThreshold(&huart1, UART_TXFIFO_THRESHOLD_1_8) != HAL_OK)
  {
    Error_Handler();
  }
  if (HAL_UARTEx_SetRxFifoThreshold(&huart1, UART_RXFIFO_THRESHOLD_1_8) != HAL_OK)
  {
    Error_Handler();
  }
  if (HAL_UARTEx_DisableFifoMode(&huart1) != HAL_OK)
  {
    Error_Handler();
  }

}

static void MX_USART2_UART_Init(void)
{

  huart2.Instance = USART2;
  huart2.Init.BaudRate = 115200;
  huart2.Init.WordLength = UART_WORDLENGTH_8B;
  huart2.Init.StopBits = UART_STOPBITS_1;
  huart2.Init.Parity = UART_PARITY_NONE;
  huart2.Init.Mode = UART_MODE_TX_RX;
  huart2.Init.HwFlowCtl = UART_HWCONTROL_NONE;
  huart2.Init.OverSampling = UART_OVERSAMPLING_16;
  huart2.Init.OneBitSampling = UART_ONE_BIT_SAMPLE_DISABLE;
  huart2.Init.ClockPrescaler = UART_PRESCALER_DIV1;
  huart2.AdvancedInit.AdvFeatureInit = UART_ADVFEATURE_NO_INIT;
  if (HAL_RS485Ex_Init(&huart2, UART_DE_POLARITY_HIGH, 0, 0) != HAL_OK)
  {
    Error_Handler();
  }
  if (HAL_UARTEx_SetTxFifoThreshold(&huart2, UART_TXFIFO_THRESHOLD_1_8) != HAL_OK)
  {
    Error_Handler();
  }
  if (HAL_UARTEx_SetRxFifoThreshold(&huart2, UART_RXFIFO_THRESHOLD_1_8) != HAL_OK)
  {
    Error_Handler();
  }
  if (HAL_UARTEx_DisableFifoMode(&huart2) != HAL_OK)
  {
    Error_Handler();
  }

}

static void MX_USART3_UART_Init(void)
{

  huart3.Instance = USART3;
  huart3.Init.BaudRate = 115200;
  huart3.Init.WordLength = UART_WORDLENGTH_8B;
  huart3.Init.StopBits = UART_STOPBITS_1;
  huart3.Init.Parity = UART_PARITY_NONE;
  huart3.Init.Mode = UART_MODE_TX_RX;
  huart3.Init.HwFlowCtl = UART_HWCONTROL_NONE;
  huart3.Init.OverSampling = UART_OVERSAMPLING_16;
  huart3.Init.OneBitSampling = UART_ONE_BIT_SAMPLE_DISABLE;
  huart3.Init.ClockPrescaler = UART_PRESCALER_DIV1;
  huart3.AdvancedInit.AdvFeatureInit = UART_ADVFEATURE_NO_INIT;
  if (HAL_UART_Init(&huart3) != HAL_OK)
  {
    Error_Handler();
  }
  if (HAL_UARTEx_SetTxFifoThreshold(&huart3, UART_TXFIFO_THRESHOLD_1_8) != HAL_OK)
  {
    Error_Handler();
  }
  if (HAL_UARTEx_SetRxFifoThreshold(&huart3, UART_RXFIFO_THRESHOLD_1_8) != HAL_OK)
  {
    Error_Handler();
  }
  if (HAL_UARTEx_DisableFifoMode(&huart3) != HAL_OK)
  {
    Error_Handler();
  }

}

static void MX_GPIO_Init(void)
{
  GPIO_InitTypeDef GPIO_InitStruct = {0};

  /* GPIO Ports Clock Enable */
  __HAL_RCC_GPIOE_CLK_ENABLE();
  __HAL_RCC_GPIOC_CLK_ENABLE();
  __HAL_RCC_GPIOH_CLK_ENABLE();
  __HAL_RCC_GPIOA_CLK_ENABLE();
  __HAL_RCC_GPIOB_CLK_ENABLE();
  __HAL_RCC_GPIOD_CLK_ENABLE();

  /*Configure GPIO pin Output Level */
  HAL_GPIO_WritePin(GPIOE, GPIO_PIN_2|GPIO_PIN_3|GPIO_PIN_4|GPIO_PIN_5
                          |GPIO_PIN_10|GPIO_PIN_13, GPIO_PIN_RESET);

  /*Configure GPIO pin Output Level */
  HAL_GPIO_WritePin(GPIOC, GPIO_PIN_13|GPIO_PIN_6|GPIO_PIN_7, GPIO_PIN_RESET);

  /*Configure GPIO pin Output Level */
  HAL_GPIO_WritePin(GPIOC, GPIO_PIN_3, GPIO_PIN_SET);

  /*Configure GPIO pin Output Level */
  HAL_GPIO_WritePin(GPIOA, GPIO_PIN_0|GPIO_PIN_15, GPIO_PIN_RESET);

  /*Configure GPIO pin Output Level */
  HAL_GPIO_WritePin(GPIOA, GPIO_PIN_4, GPIO_PIN_SET);

  /*Configure GPIO pin Output Level */
  HAL_GPIO_WritePin(GPIOB, GPIO_PIN_1|GPIO_PIN_2|GPIO_PIN_4, GPIO_PIN_RESET);

  /*Configure GPIO pin Output Level */
  HAL_GPIO_WritePin(GPIOB, GPIO_PIN_12, GPIO_PIN_SET);

  /*Configure GPIO pin Output Level */
  HAL_GPIO_WritePin(GPIOD, GPIO_PIN_2|GPIO_PIN_3|GPIO_PIN_4|GPIO_PIN_5, GPIO_PIN_RESET);

  /*Configure GPIO pin Output Level */
  HAL_GPIO_WritePin(GPIOD, GPIO_PIN_6, GPIO_PIN_SET);

  /*Configure GPIO pins : PE2 PE3 PE4 PE5
                           PE10 PE13 */
  GPIO_InitStruct.Pin = GPIO_PIN_2|GPIO_PIN_3|GPIO_PIN_4|GPIO_PIN_5
                          |GPIO_PIN_10|GPIO_PIN_13;
  GPIO_InitStruct.Mode = GPIO_MODE_OUTPUT_PP;
  GPIO_InitStruct.Pull = GPIO_NOPULL;
  GPIO_InitStruct.Speed = GPIO_SPEED_FREQ_LOW;
  HAL_GPIO_Init(GPIOE, &GPIO_InitStruct);

  /*Configure GPIO pins : PC13 PC3 PC6 PC7 */
  GPIO_InitStruct.Pin = GPIO_PIN_13|GPIO_PIN_3|GPIO_PIN_6|GPIO_PIN_7;
  GPIO_InitStruct.Mode = GPIO_MODE_OUTPUT_PP;
  GPIO_InitStruct.Pull = GPIO_NOPULL;
  GPIO_InitStruct.Speed = GPIO_SPEED_FREQ_LOW;
  HAL_GPIO_Init(GPIOC, &GPIO_InitStruct);

  /*Configure GPIO pins : PA0 PA4 PA15 */
  GPIO_InitStruct.Pin = GPIO_PIN_0|GPIO_PIN_4|GPIO_PIN_15;
  GPIO_InitStruct.Mode = GPIO_MODE_OUTPUT_PP;
  GPIO_InitStruct.Pull = GPIO_NOPULL;
  GPIO_InitStruct.Speed = GPIO_SPEED_FREQ_LOW;
  HAL_GPIO_Init(GPIOA, &GPIO_InitStruct);

  /*Configure GPIO pins : PC4 PC5 PC8 */
  GPIO_InitStruct.Pin = GPIO_PIN_4|GPIO_PIN_5|GPIO_PIN_8;
  GPIO_InitStruct.Mode = GPIO_MODE_INPUT;
  GPIO_InitStruct.Pull = GPIO_NOPULL;
  HAL_GPIO_Init(GPIOC, &GPIO_InitStruct);

  /*Configure GPIO pins : PB1 PB2 PB12 PB4 */
  GPIO_InitStruct.Pin = GPIO_PIN_1|GPIO_PIN_2|GPIO_PIN_12|GPIO_PIN_4;
  GPIO_InitStruct.Mode = GPIO_MODE_OUTPUT_PP;
  GPIO_InitStruct.Pull = GPIO_NOPULL;
  GPIO_InitStruct.Speed = GPIO_SPEED_FREQ_LOW;
  HAL_GPIO_Init(GPIOB, &GPIO_InitStruct);

  /*Configure GPIO pins : PE9 PE11 PE12 */
  GPIO_InitStruct.Pin = GPIO_PIN_9|GPIO_PIN_11|GPIO_PIN_12;
  GPIO_InitStruct.Mode = GPIO_MODE_INPUT;
  GPIO_InitStruct.Pull = GPIO_NOPULL;
  HAL_GPIO_Init(GPIOE, &GPIO_InitStruct);

  /*Configure GPIO pin : PE14 */
  GPIO_InitStruct.Pin = GPIO_PIN_14;
  GPIO_InitStruct.Mode = GPIO_MODE_ANALOG;
  GPIO_InitStruct.Pull = GPIO_NOPULL;
  HAL_GPIO_Init(GPIOE, &GPIO_InitStruct);

  /*Configure GPIO pins : PD2 PD3 PD4 PD5
                           PD6 */
  GPIO_InitStruct.Pin = GPIO_PIN_2|GPIO_PIN_3|GPIO_PIN_4|GPIO_PIN_5
                          |GPIO_PIN_6;
  GPIO_InitStruct.Mode = GPIO_MODE_OUTPUT_PP;
  GPIO_InitStruct.Pull = GPIO_NOPULL;
  GPIO_InitStruct.Speed = GPIO_SPEED_FREQ_LOW;
  HAL_GPIO_Init(GPIOD, &GPIO_InitStruct);

  /*Configure GPIO pin : PD7 */
  GPIO_InitStruct.Pin = GPIO_PIN_7;
  GPIO_InitStruct.Mode = GPIO_MODE_INPUT;
  GPIO_InitStruct.Pull = GPIO_NOPULL;
  HAL_GPIO_Init(GPIOD, &GPIO_InitStruct);

  /*Configure GPIO pin : PB7 */
  GPIO_InitStruct.Pin = GPIO_PIN_7;
  GPIO_InitStruct.Mode = GPIO_MODE_INPUT;
  GPIO_InitStruct.Pull = GPIO_NOPULL;
  HAL_GPIO_Init(GPIOB, &GPIO_InitStruct);

  /*AnalogSwitch Config */
  HAL_SYSCFG_AnalogSwitchConfig(SYSCFG_SWITCH_PC3, SYSCFG_SWITCH_PC3_CLOSE);

  /*AnalogSwitch Config */
  HAL_SYSCFG_AnalogSwitchConfig(SYSCFG_SWITCH_PA0, SYSCFG_SWITCH_PA0_CLOSE);

}

void StartDefaultTask(void *argument)
{
  for(;;)
  {
    osDelay(1);
  }
}

 /* MPU Configuration */

void MPU_Config(void)
{
  MPU_Region_InitTypeDef MPU_InitStruct = {0};

  /* Disables the MPU */
  HAL_MPU_Disable();

  /** Initializes and configures the Region and the memory to be protected
  */
  MPU_InitStruct.Enable = MPU_REGION_ENABLE;
  MPU_InitStruct.Number = MPU_REGION_NUMBER0;
  MPU_InitStruct.BaseAddress = 0x0;
  MPU_InitStruct.Size = MPU_REGION_SIZE_4GB;
  MPU_InitStruct.SubRegionDisable = 0x87;
  MPU_InitStruct.TypeExtField = MPU_TEX_LEVEL0;
  MPU_InitStruct.AccessPermission = MPU_REGION_NO_ACCESS;
  MPU_InitStruct.DisableExec = MPU_INSTRUCTION_ACCESS_DISABLE;
  MPU_InitStruct.IsShareable = MPU_ACCESS_SHAREABLE;
  MPU_InitStruct.IsCacheable = MPU_ACCESS_NOT_CACHEABLE;
  MPU_InitStruct.IsBufferable = MPU_ACCESS_NOT_BUFFERABLE;

  HAL_MPU_ConfigRegion(&MPU_InitStruct);
  /* Enables the MPU */
  HAL_MPU_Enable(MPU_PRIVILEGED_DEFAULT);

}

void HAL_TIM_PeriodElapsedCallback(TIM_HandleTypeDef *htim)
{
  if (htim->Instance == TIM6)
  {
    HAL_IncTick();
  }
}

void Error_Handler(void)
{
  __disable_irq();
  while (1)
  {
  }
}
